# A31G314 register map
Vendor: ABOV Semiconductor Co., Ltd.; Series: A31G314; File version: 1.0
CPU: CM0PLUS r0p1, little endian, no MPU, no FPU, VTOR, 2 interrupt priority bits
Registers are 32-bit, read-write, reset 0x0 unless marked. A register's access mark holds for its fields unless they carry their own. Offsets are from the block's base; [hi:lo] are bit positions; {n}, {i} and the like mark numbered series.

## I2C0
Base 0x40004800
Same registers: I2C1 0x40004900, I2C2 0x40004A00
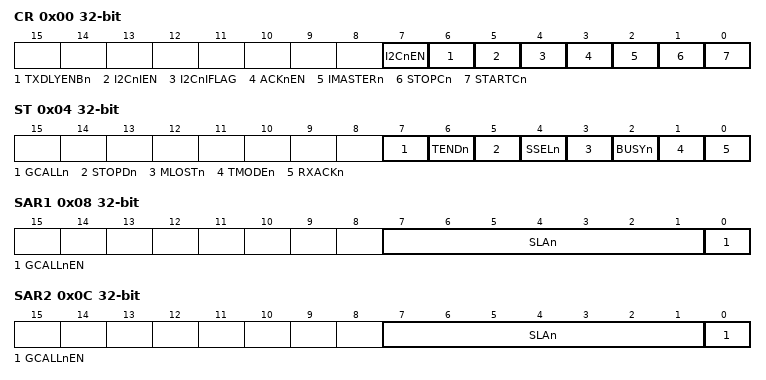
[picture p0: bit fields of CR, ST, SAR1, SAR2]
0x00 CR — I2Cn Control Register
  [7] I2CnEN — Activate I2Cn Block by supplying
  [6] TXDLYENBn — I2CnSDHR Register Control bit
  [5] I2CnIEN — I2Cn Interrupt Enable bit
  [4] I2CnIFLAG — I2Cn Interrupt Flag bit. This bit is cleared when write any values in the I2CnST register.
  [3] ACKnEN — Controls ACK signal generation at ninth SCL period. Notes) ACK signal is output (SDA = 0) for the following 3 cases. Where x = 0 and 1. 1. When received address packet equals to SLAx[6:0] bits in I2CnSARx register. 2. When received address packet equals to value 0x00 with GCALLn enabled. 3. When I2Cn operates as a receiver (master or slave)
  [2] IMASTERn ro — Represent Operation Mode of I2Cn
  [1] STOPCn — STOP Condition Generation When I2Cn is master.
  [0] STARTCn — START Condition Generation When I2Cn is master.
0x04 ST — I2Cn Status Register
  [7] GCALLn — This bit has different meaning depending on whether I2C is master or slave. When I2C is a master, this bit represents whether it received AACK (address ACK) from slave.
  [6] TENDn — This bit is set when 1-byte of data is transferred completely.
  [5] STOPDn — This bit is set when a STOP condition is detected.
  [4] SSELn — This bit is set when I2C is addressed by other master.
  [3] MLOSTn — This bit represents the result of bus arbitration in master mode.
  [2] BUSYn — This bit reflects bus status.
  [1] TMODEn ro — This bit is used to indicate whether I2C is transmitter or receiver.
  [0] RXACKn — This bit shows the state of ACK signal.
0x08 SAR1 — I2Cn Slave Address Register 1
  [7:1] SLAn — These bits configure the slave address 0 in slave mode.
  [0] GCALLnEN — This bit decides whether I2Cn allows general call address 0 or not in I2Cn slave mode.
0x0C SAR2 — I2Cn Slave Address Register 2
  [7:1] SLAn — These bits configure the slave address 1 in slave mode.
  [0] GCALLnEN — This bit decides whether I2Cn allows general call address 1 or not in I2Cn slave mode.
0x10 DR — I2Cn Data Register
  [7:0] DATA — The I2CnDR Transmit buffer and Receive buffer share the same I/O address with this DATA register. The Transmit Data Buffer is the destination for data written to the I2CnDR register. Reading the I2CnDR register returns the contents of the Receive Buffer.
0x14 SDHR reset 0x1 — I2Cn SDA Hold Time Register
  [11:0] HLDT — This register is used to control SDA output timing from the falling edge of SCL. Note that SDA is changed after tPCLK X (I2CnSDHR+2). In master mode, load half the value of I2CnSCLR to this register to make SDA change in the middle of SCL. In slave mode, configure this register regarding the frequency of SCL from master. The SDA is changed after tPCLK X (I2CnSDHR+2) in master mode. So, to insure operation in slave mode, the value tPCLK X (I2CnSDHR + 2) must be smaller than the period of SCL.
0x18 SCLR reset 0x3F — I2Cn SCL Low Period Register
  [11:0] SCLL — This register defines the low period of SCL in master mode. The base clock is PCLK and the period is calculated by the formula: tPCLK X (4 X I2CnSCLR + 2) where tPCLK is the period of PCLK.
0x1C SCHR reset 0x3F — I2Cn SCL High Period Register
  [11:0] SCLH — This register defines the high period of SCL in master mode. The base clock is PCLK and the period is calculated by the formula: tPCLK X (4 X I2CnSCHR + 2) where tPCLK is the period of PCLK.

## ADC — 12-BIT A/D CONVERTER
Base 0x40003000
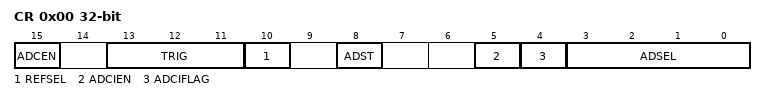
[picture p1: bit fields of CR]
0x00 CR — A/D Converter Control Register
  [15] ADCEN — A/DC Module Enable bit (The A/DC is automatically disabled at power down mode)
    0=DISABLE_ADC (Disable A/DC module operation); 1=ENABLE_ADC (Enable A/DC module operation)
  [13:11] TRIG — A/DC Trigger Signal Selection bits
    0=ADST; 1=T10_A_MATCH (Timer 10 A-match signal); 2=T11_A_MATCH (Timer 11 A-match signal); 3=T12_A_MATCH (Timer 12 A-match signal); 4=T30_SIGNAL (A/DC trigger signal from timer 30)
  [10] REFSEL — A/DC Reference Selection bit
    0=VDD (Select analog power (VDD)); 1=AVREF (Select external reference (AVREF))
  [8] ADST — A/DC Conversion Start bit. This bit is automatically cleared to "0b" after operation
    0=NONE (No effect); 1=START_AD_CONVERSION (Trigger signal generation for conversion start)
  [5] ADCIEN — A/DC Interrupt Enable bit
    0=DISABLE_ADC_INT (Disable A/DC interrupt); 1=ENABLE_ADC_INT (Enable A/DC interrupt)
  [4] ADCIFLAG — A/DC Interrupt Flag bit
    0=ADC_IF_CLR (No request occurred); 1=ADC_IF_SET (Request occurred, This bit is cleared to '0' when write '1'.)
  [3:0] ADSEL — A/D Converter Channel Selection bits
    {v}=AN{v} (v=0..10); 15=VDD18 (VDD15)
0x04 DR ro — A/D Converter Data Register
  [11:0] ADDATA — A/D Converter Result Data bits
0x08 PREDR reset 0xF — A/D Converter Prescaler Data Register
  [4:0] PRED — A/D Converter Prescaler Data bits.
